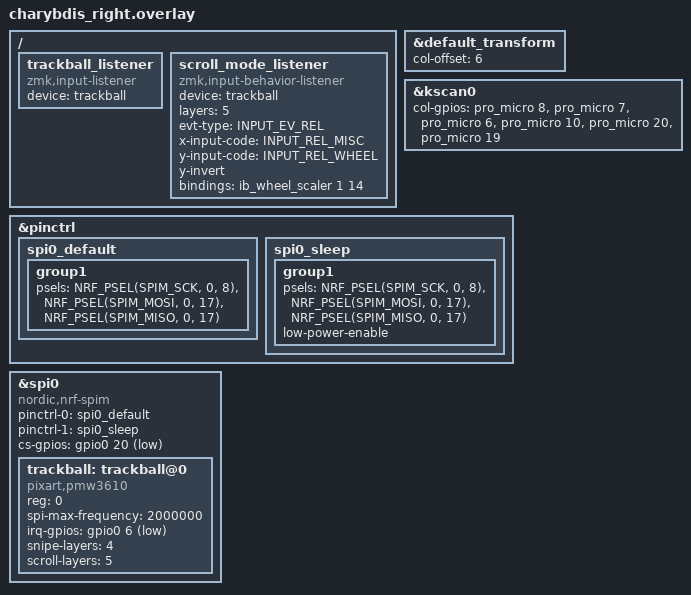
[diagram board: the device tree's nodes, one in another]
#include "charybdis.dtsi"

&default_transform {
	col-offset = <6>;
};

&kscan0 {
	col-gpios
		= <&pro_micro 8 (GPIO_ACTIVE_HIGH | GPIO_PULL_DOWN)>
		, <&pro_micro 7 (GPIO_ACTIVE_HIGH | GPIO_PULL_DOWN)>
		, <&pro_micro 6 (GPIO_ACTIVE_HIGH | GPIO_PULL_DOWN)>
		, <&pro_micro 10 (GPIO_ACTIVE_HIGH | GPIO_PULL_DOWN)>
		, <&pro_micro 20 (GPIO_ACTIVE_HIGH | GPIO_PULL_DOWN)>
		, <&pro_micro 19 (GPIO_ACTIVE_HIGH | GPIO_PULL_DOWN)>
  ;
};

&pinctrl {
    spi0_default: spi0_default {
        group1 {
            psels = <NRF_PSEL(SPIM_SCK, 0, 8)>,
                <NRF_PSEL(SPIM_MOSI, 0, 17)>,
                <NRF_PSEL(SPIM_MISO, 0, 17)>;
        };
    };

    spi0_sleep: spi0_sleep {
        group1 {
            psels = <NRF_PSEL(SPIM_SCK, 0, 8)>,
                <NRF_PSEL(SPIM_MOSI, 0, 17)>,
                <NRF_PSEL(SPIM_MISO, 0, 17)>;
            low-power-enable;
        };
    };
};

&spi0 {
    status = "okay";
    compatible = "nordic,nrf-spim";
    pinctrl-0 = <&spi0_default>;
    pinctrl-1 = <&spi0_sleep>;
    pinctrl-names = "default", "sleep";
    cs-gpios = <&gpio0 20 GPIO_ACTIVE_LOW>;

    trackball: trackball@0 {
        status = "okay";
        compatible = "pixart,pmw3610";
        reg = <0>;
        spi-max-frequency = <2000000>;
        irq-gpios = <&gpio0 6 (GPIO_ACTIVE_LOW | GPIO_PULL_UP)>;

        /*   optional features   */
        snipe-layers = <4>;
        scroll-layers = <5>;
        /* automouse-layer = <4>; */
    };
};

/ {
  trackball_listener {
    compatible = "zmk,input-listener";
    device = <&trackball>;
  };

  // Добавленный listener для скролла на слое 5
  scroll_mode_listener: scroll_mode_listener {
    compatible = "zmk,input-behavior-listener";
    device = <&trackball>;
    layers = <5>;  // Активен на слое SCROLL
    evt-type = <INPUT_EV_REL>;
    x-input-code = <INPUT_REL_MISC>;  // Горизонтальный скролл
    y-input-code = <INPUT_REL_WHEEL>;  // Вертикальный скролл
    y-invert;  // Инвертировать Y для естественного скролла
    bindings = <&ib_wheel_scaler 1 14>;  // Скорость скролла (настрой 14 по вкусу)
  };
};
